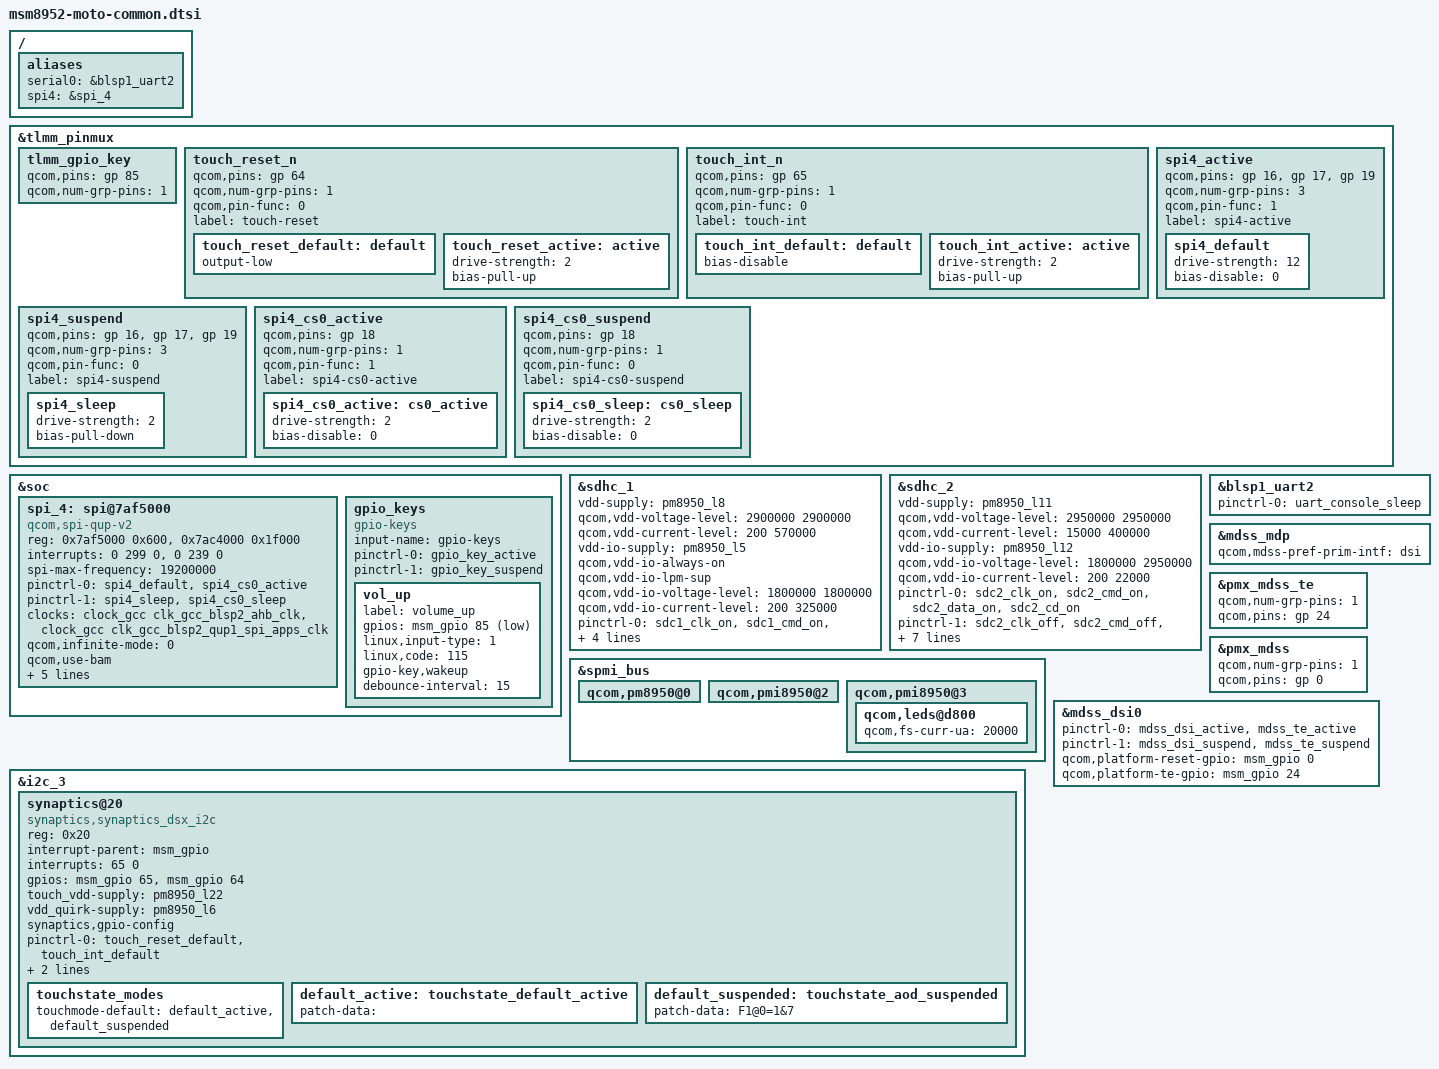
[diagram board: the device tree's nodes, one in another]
/* Copyright (c) 2015, Motorola Mobility Inc. All rights reserved.
 *
 * This program is free software; you can redistribute it and/or modify
 * it under the terms of the GNU General Public License version 2 and
 * only version 2 as published by the Free Software Foundation.
 *
 * This program is distributed in the hope that it will be useful,
 * but WITHOUT ANY WARRANTY; without even the implied warranty of
 * MERCHANTABILITY or FITNESS FOR A PARTICULAR PURPOSE.  See the
 * GNU General Public License for more details.
 */


#include "msm8952.dtsi"
#include "msm8952-pinctrl.dtsi"

/ {
	aliases {
		serial0 = &blsp1_uart2;
		spi4 = &spi_4;
		/delete-property/ i2c5;
		/delete-property/ spi0;
	};
};

&tlmm_pinmux {
	tlmm_gpio_key {
			qcom,pins = <&gp 85>;
			qcom,num-grp-pins = <1>;
	};

	touch_reset_n {
		qcom,pins = <&gp 64>;
		qcom,num-grp-pins = <1>;
		qcom,pin-func = <0>;
		label = "touch-reset";

		touch_reset_default: default {
			output-low;
		};

		touch_reset_active: active {
			drive-strength = <2>;
			bias-pull-up; /* pull-up */
		};
	};

	touch_int_n {
		qcom,pins = <&gp 65>;
		qcom,num-grp-pins = <1>;
		qcom,pin-func = <0>;
		label = "touch-int";

		touch_int_default: default {
			bias-disable;
		};

		touch_int_active: active {
			drive-strength = <2>;
			bias-pull-up; /* pull-up */
		};
	};

	spi4_active {
		/* BLSP5 MOSI, MISO, CLK */
		qcom,pins = <&gp 16>, <&gp 17>, <&gp 19>;
		qcom,num-grp-pins = <3>;
		qcom,pin-func = <1>;
		label = "spi4-active";
		/* active state */
		spi4_default: spi4_default {
			drive-strength = <12>; /* 12 MA */
			bias-disable = <0>; /* No PULL */
		};
	};

	spi4_suspend {
		/* BLSP5 MOSI, MISO, CLK */
		qcom,pins = <&gp 16>, <&gp 17>, <&gp 19>;
		qcom,num-grp-pins = <3>;
		qcom,pin-func = <0>;
		label = "spi4-suspend";
		/* suspended state */
		spi4_sleep: spi4_sleep {
			drive-strength = <2>; /* 2 MA */
			bias-pull-down; /* PULL Down */
		};
	};

	spi4_cs0_active {
		/* BLSP5 CS */
		qcom,pins = <&gp 18>;
		qcom,num-grp-pins = <1>;
		qcom,pin-func = <1>;
		label = "spi4-cs0-active";
		spi4_cs0_active: cs0_active {
			drive-strength = <2>;
			bias-disable = <0>;
		};
	};

	spi4_cs0_suspend {
		/* BLSP5 CS */
		qcom,pins = <&gp 18>;
		qcom,num-grp-pins = <1>;
		qcom,pin-func = <0>;
		label = "spi4-cs0-suspend";
		spi4_cs0_sleep: cs0_sleep {
			drive-strength = <2>;
			bias-disable = <0>;
		};
	};
};

&soc {
	/delete-node/ spi@78B5000;
	/delete-node/ i2c@7af5000;

	spi_4: spi@7af5000 { /* BLSP2 QUP1 */
		compatible = "qcom,spi-qup-v2";
		#address-cells = <1>;
		#size-cells = <0>;
		reg-names = "spi_physical", "spi_bam_physical";
		reg = <0x7af5000 0x600>,
		      <0x7ac4000 0x1f000>;
		interrupt-names = "spi_irq", "spi_bam_irq";
		/* IRQ 239 for BLSP2 */
		interrupts = <0 299 0>, <0 239 0>;
		spi-max-frequency = <19200000>;
		pinctrl-names = "spi_default", "spi_sleep";
		pinctrl-0 = <&spi4_default &spi4_cs0_active>;
		pinctrl-1 = <&spi4_sleep &spi4_cs0_sleep>;
		clock-names = "iface_clk", "core_clk";
		clocks = <&clock_gcc clk_gcc_blsp2_ahb_clk>,
			 <&clock_gcc clk_gcc_blsp2_qup1_spi_apps_clk>;
		qcom,infinite-mode = <0>;
		qcom,use-bam;
		qcom,use-pinctrl;
		qcom,ver-reg-exists;
		/* need to check pipe index setting*/
		qcom,bam-consumer-pipe-index = <4>;
		qcom,bam-producer-pipe-index = <5>;
		/* master-id for BLSP2 is MSM_BUS_MASTER_BLSP_2 or 84 */
		qcom,master-id = <84>;
		status = "ok";
	};

	/delete-node/ eldo2;

	gpio_keys {
		compatible = "gpio-keys";
		input-name = "gpio-keys";
		pinctrl-names = "tlmm_gpio_key_active","tlmm_gpio_key_suspend";
		pinctrl-0 = <&gpio_key_active>;
		pinctrl-1 = <&gpio_key_suspend>;

		vol_up {
			label = "volume_up";
			gpios = <&msm_gpio 85 0x1>;
			linux,input-type = <1>;
			linux,code = <115>;
			gpio-key,wakeup;
			debounce-interval = <15>;
		};
	};
};

&sdhc_1 {
	vdd-supply = <&pm8950_l8>;
	qcom,vdd-voltage-level = <2900000 2900000>;
	qcom,vdd-current-level = <200 570000>;

	vdd-io-supply = <&pm8950_l5>;
	qcom,vdd-io-always-on;
	qcom,vdd-io-lpm-sup;
	qcom,vdd-io-voltage-level = <1800000 1800000>;
	qcom,vdd-io-current-level = <200 325000>;

	pinctrl-names = "active", "sleep";
	pinctrl-0 = <&sdc1_clk_on &sdc1_cmd_on &sdc1_data_on &sdc1_rclk_on>;
	pinctrl-1 = <&sdc1_clk_off &sdc1_cmd_off &sdc1_data_off &sdc1_rclk_off>;

	qcom,nonremovable;

	status = "ok";
};

&sdhc_2 {
	vdd-supply = <&pm8950_l11>;
	qcom,vdd-voltage-level = <2950000 2950000>;
	qcom,vdd-current-level = <15000 400000>;

	vdd-io-supply = <&pm8950_l12>;
	qcom,vdd-io-voltage-level = <1800000 2950000>;
	qcom,vdd-io-current-level = <200 22000>;

	pinctrl-names = "active", "sleep";
	pinctrl-0 = <&sdc2_clk_on &sdc2_cmd_on &sdc2_data_on &sdc2_cd_on>;
	pinctrl-1 = <&sdc2_clk_off &sdc2_cmd_off &sdc2_data_off &sdc2_cd_off>;

	#address-cells = <0>;
	interrupt-parent = <&sdhc_2>;
	interrupts = <0 1 2>;
	#interrupt-cells = <1>;
	interrupt-map-mask = <0xffffffff>;
	interrupt-map = <0 &intc 0 125 0
			1 &intc 0 221 0
			2 &msm_gpio 67 0>;
	interrupt-names = "hc_irq", "pwr_irq", "status_irq";
	cd-gpios = <&msm_gpio 67 0x1>;

	status = "ok";
};

&blsp1_uart2 {
	status = "ok";
	pinctrl-names = "default";
	pinctrl-0 = <&uart_console_sleep>;
};

&spmi_bus {
	qcom,pm8950@0 {
		/delete-node/ qcom,leds@a300;
	};

	qcom,pmi8950@2 {
		/delete-node/ qcom,leds@a100;
	};

	qcom,pmi8950@3 {
		qcom,leds@d800 {
			qcom,fs-curr-ua = <20000>;
			/delete-property/ qcom,en-ext-pfet-sc-pro;
		};
	};
};

&mdss_mdp {
	qcom,mdss-pref-prim-intf = "dsi";
};

&pmx_mdss_te {
	qcom,num-grp-pins = <1>;
	qcom,pins = <&gp 24>;
};

&pmx_mdss {
	qcom,num-grp-pins = <1>;
	qcom,pins = <&gp 0>;
};

&mdss_dsi0 {
	pinctrl-names = "mdss_default", "mdss_sleep";
	pinctrl-0 = <&mdss_dsi_active &mdss_te_active>;
	pinctrl-1 = <&mdss_dsi_suspend &mdss_te_suspend>;

	qcom,platform-reset-gpio = <&msm_gpio 0 0>;
	qcom,platform-te-gpio = <&msm_gpio 24 0>;

	/delete-property/ vdd-supply;
	/delete-property/ vddio-supply;
	/delete-property/ lab-supply;
	/delete-property/ ibb-supply;
};

&i2c_3 { /* BLSP1 QUP3 */
	synaptics@20 {
		compatible = "synaptics,synaptics_dsx_i2c";
		reg = <0x20>;
		interrupt-parent = <&msm_gpio>;
		interrupts = <65 0>;
		gpios = <&msm_gpio 65 0>, /* IRQ */
			<&msm_gpio 64 0>; /* RESET */
		touch_vdd-supply = <&pm8950_l22>;
		vdd_quirk-supply = <&pm8950_l6>;
		/*vcc_i2c-supply = <&pm8950_l6>;*/
		synaptics,gpio-config;
		/* pins used by touchscreen */
		pinctrl-names = "default", "active";
		pinctrl-0 = <&touch_reset_default &touch_int_default>;
		pinctrl-1 = <&touch_reset_active &touch_int_active>;
		touchstate_modes {
			touchmode-default = <&default_active &default_suspended>;
		};
		default_active: touchstate_default_active {
			patch-data = "";
		};
		default_suspended: touchstate_aod_suspended {
			patch-data = "F1@0=1&7";
		};
	};
};
